# evalsoc register map
Vendor: Nuclei; Series: Nuclei Evaluation SoC
CPU: Evalsoc, little endian
Registers are 32-bit, read-write, reset 0x0 unless marked. A register's access mark holds for its fields unless they carry their own. Offsets are from the block's base; [hi:lo] are bit positions; 'fields as' and 'values as' point back to an identical list.

## IINFO — Some internal information is defined here by memory map registers. IINFO shows internal peripherals configurations or controls some micro-architecture functions.
Base 0x18000000
0x00 mpasize ro — Physical Size register. Shows the physical address size supported by the hardware.
  [31:0] PA_SIZE — Physical Size. If the PA_SIZE is 48, the number of this register is 48.
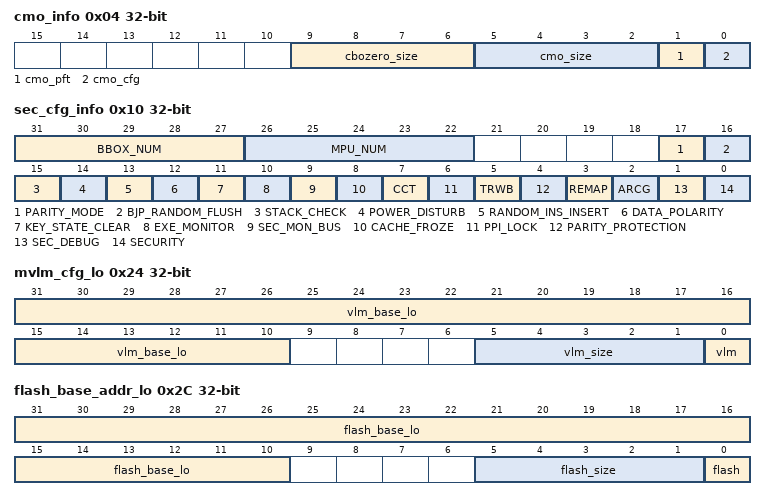
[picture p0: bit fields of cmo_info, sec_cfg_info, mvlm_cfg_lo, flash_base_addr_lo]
0x04 cmo_info ro — Shows Nuclei series RISC-V Standard CMO implementation information.
  [9:6] cbozero_size — The size of the cache block for cbo.zero instructions.<br>0: 4 bytes<br>1: 8 bytes<br>2: 16 bytes<br>3: 32 bytes<br>4: 64 bytes<br>5: 128 bytes<br>6: 256 bytes<br>7: 512 bytes
  [5:2] cmo_size — The size of the cache block for management and prefetch instructions.<br>0: 4 bytes<br>1: 8 bytes<br>2: 16 bytes<br>3: 32 bytes<br>4: 64 bytes<br>5: 128 bytes<br>6: 256 bytes<br>7: 512 bytes<br>Currently in Nuclei series core, the size is same with D-Cache cacheline.
  [1] cmo_pft — Global configuration for CMO Extension's prefetch support:<br>0: No CMO Extension's prefetch support, the prefetch.0/prefetch.r/prefetch.w are all implemented as nop.<br>1: Has CMO Extension's prefetch support.
  [0] cmo_cfg — Global configuration for CMO Extension support:<br>0: No CMO Extension support.<br>1: Has CMO Extension support.<br>Currently in Nuclei series core, if there is D-Cache or I-Cache, then it has CMO support.
0x08 sec_base_addr_lo ro — Shows the external security controller lower 32-bit base address information.
  [31:0] sec_base_addr_lo — Security controller base address low.
0x0C sec_base_addr_hi ro — Shows the external security controller higher 32-bit base address information.
  [31:0] sec_base_addr_hi — Security controller base address high.
0x10 sec_cfg_info ro — Shows the security feature supported by CPU.
  [31:27] BBOX_NUM — The value of this field represents the number of black box debugging entries:<br>* 0: indicates that the current core does not support the black box debugging feature.<br>* Non-zero: indicates that the current core supports the black box debugging feature.
  [26:22] MPU_NUM — The value of this field represents the number of mpu entries:<br>* 0: indicates that the current core does not support the mpu feature.<br>* Non-zero: indicates that the current core supports the mpu feature.
  [17] PARITY_MODE — Parity mode, only active when parity_protection enable.<br>* 0: 1-bit parity check mode<br>* 1: 4-bit parity check mode.
  [16] BJP_RANDOM_FLUSH — BJP instruction can send random flush feature support:<br>* 0: Not support<br>* 1: Support
  [15] STACK_CHECK — Stack check feature support:<br>* 0: Not support<br>* 1: Support
  [14] POWER_DISTURB — Power scrambling feature support.<br>* 0: Not support<br>* 1: Support
  [13] RANDOM_INS_INSERT — Random instruction insert feature support.<br>* 0: Not support<br>* 1: Support
  [12] DATA_POLARITY — Data polarity feature support.<br>* 0: Not support<br>* 1: Support
  [11] KEY_STATE_CLEAR — Key state clear feature support.<br>* 0: Not support<br>* 1: Support
  [10] EXE_MONITOR — Execution monitor feature support.<br>* 0: Not support<br>* 1: Support, Core will output some internal signal.
  [9] SEC_MON_BUS — Security monitor bus feature support:<br>* 0: Not support<br>* 1: Support, Core will output some error information on this bus.
  [8] CACHE_FROZE — Cache Frozen feature support:<br>* 0: Not support<br>* 1: Support, cache miss will not refill data into cache to protect the secure and critical code.
  [7] CCT — Instruction execution time consistency feature support:<br>* 0: Not support<br>* 1: Support
  [6] PPI_LOCK — PPI Lock feature support:<br>* 0: Not support<br>* 1: Support
  [5] TRWB — Garbage register write-back feature support:<br>* 0: Not support<br>* 1: Support
  [4] PARITY_PROTECTION — Register parity protection feature support:<br>* 0: Not support<br>* 1: Support
  [3] REMAP — Vector table remap feature support:<br>* 0: Not support<br>* 1: Support
  [2] ARCG — Architecture random clock gate feature support:<br>* 0: Not support<br>* 1: Support
  [1] SEC_DEBUG — Secure debug feature support:<br>* 0: Not support<br>* 1: Support
  [0] SECURITY — Security feature support:<br>* 0: Not support<br>* 1: Support
0x24 mvlm_cfg_lo ro — Shows the VLM configurations information (lower 32 bits).
  [31:10] vlm_base_lo — VLM base address [31:10]
  [5:1] vlm_size — 0: 0 bytes<br>1: 1K bytes<br>2: 2K bytes<br>3: 4K bytes<br>4: 8K bytes<br>5: 16K bytes<br>6: 32K bytes<br>7: 64K bytes<br>8: 128K bytes<br>9: 256K bytes<br>10: 512K bytes<br>11: 1M bytes<br>12: 2M bytes<br>13: 4M bytes<br>14: 8M bytes<br>15: 16M bytes<br>16: 32M bytes<br>17: 64M bytes<br>18: 128M bytes<br>19: 256M bytes<br>20: 512M bytes<br>21: 1G bytes<br>22: 2G bytes<br>23: 4G bytes<br>others: reserved
  [0] vlm — Shows the hardware has VLM configuration or not. 0 means no, 1 means yes.
0x28 mvlm_cfg_hi ro — Shows the higher 32 bit of VLM base address.
  [31:0] vlm_base_hi — VLM base address high.
0x2C flash_base_addr_lo ro — Shows the flash bus configurations information (lower 32 bits).
  [31:10] flash_base_lo — flash bus base address [31:10]
  [5:1] flash_size — 0: 0 bytes<br>1: 1K bytes<br>2: 2K bytes<br>3: 4K bytes<br>4: 8K bytes<br>5: 16K bytes<br>6: 32K bytes<br>7: 64K bytes<br>8: 128K bytes<br>9: 256K bytes<br>10: 512K bytes<br>11: 1M bytes<br>12: 2M bytes<br>13: 4M bytes<br>14: 8M bytes<br>15: 16M bytes<br>16: 32M bytes<br>17: 64M bytes<br>18: 128M bytes<br>19: 256M bytes<br>20: 512M bytes<br>21: 1G bytes<br>22: 2G bytes<br>23: 4G bytes<br>others: reserved
  [0] flash — Shows the hardware has flash bus configuration or not.<br>0: means no<br>1: means yes.
0x30 flash_base_addr_hi ro — Shows the higher 32 bit of flash bus base address.
  [31:0] flash_base_hi — Flash bus information
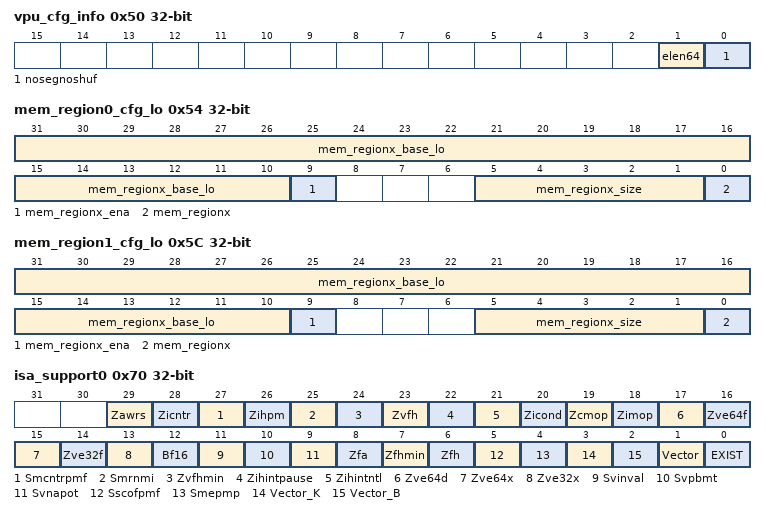
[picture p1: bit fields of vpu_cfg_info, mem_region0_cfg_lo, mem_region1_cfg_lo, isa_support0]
0x50 vpu_cfg_info ro — Shows the VPU configurations information.
  [1] elen64 — 1: Support elen=64 when configure VPU<br>0: No support elen=64 when configure VPU
  [0] nosegnoshuf — 1: No segment and no shuf feature when configure VPU<br>0: Support segment and shuf feature when configure VPU
0x54 mem_region0_cfg_lo — Hardware memory-region0 information (lower 32 bits).
  [31:10] mem_regionx_base_lo ro — mem_regionx's low 32 bits base address(aligned 1k)
  [9] mem_regionx_ena — 0: disable<br>1: enable
  [5:1] mem_regionx_size ro — 0: 0 bytes<br>1: 1K bytes<br>2: 2K bytes<br>3: 4K bytes<br>4: 8K bytes<br>5: 16K bytes<br>6: 32K bytes<br>7: 64K bytes<br>8: 128K bytes<br>9: 256K bytes<br>10: 512K bytes<br>11: 1M bytes<br>12: 2M bytes<br>13: 4M bytes<br>14: 8M bytes<br>15: 16M bytes<br>16: 32M bytes<br>17: 64M bytes<br>18: 128M bytes<br>19: 256M bytes<br>20: 512M bytes<br>21: 1G bytes<br>22: 2G bytes<br>23: 4G bytes<br>others: reserved
  [0] mem_regionx ro — 0: don't support mem_regionx<br>1: support mem_regionx
0x58 mem_region0_cfg_hi ro — Hardware memory-region0 information (higher 32 bits).
  [31:0] mem_regionx_base_hi — mem_regionx's high 32 bits base address
0x5C mem_region1_cfg_lo — Hardware memory-region1 information (lower 32 bits).
  fields as mem_region0_cfg_lo
0x60 mem_region1_cfg_hi ro — Hardware memory-region1 information (higher 32 bits).
  [31:0] mem_regionx_base_hi — mem_regionx's high 32 bits base address
0x70 isa_support0 ro — Shows the hardware support RISC-V ISA (part 0).
  [29] Zawrs — Zawrs extension support.
  [28] Zicntr — Zicntr extension support.
  [27] Smcntrpmf — Smcntrpmf extension support.
  [26] Zihpm — Zihpm extension support.
  [25] Smrnmi — Smrnmi extension support.
  [24] Zvfhmin — Zvfhmin extension support.
  [23] Zvfh — Zvfh extension support.
  [22] Zihintpause — Zihintpause extension support.
  [21] Zihintntl — Zihintntl extension support.
  [20] Zicond — Zicond extension support.
  [19] Zcmop — Zcmop extension support.
  [18] Zimop — Zimop extension support.
  [17] Zve64d — Zve64d extension support.
  [16] Zve64f — Zve64f extension support.
  [15] Zve64x — Zve64x extension support.
  [14] Zve32f — Zve32f extension support.
  [13] Zve32x — Zve32x extension support.
  [12] Bf16 — Bf16 extension support.
  [11] Svinval — Svinval extension support.
  [10] Svpbmt — Svpbmt extension support.
  [9] Svnapot — Svnapot extension support.
  [8] Zfa — Zfa extension support.
  [7] Zfhmin — Zfhmin extension support.
  [6] Zfh — Zfh extension support.
  [5] Sscofpmf — Sscofpmf extension support.
  [4] Smepmp — Smepmp extension support.
  [3] Vector_K — Vector-K extension support.
  [2] Vector_B — Vector-B extension support.
  [1] Vector — Vector extension support.
  [0] EXIST — This register exist.<br>1: This register exist<br>0: This register it not exist
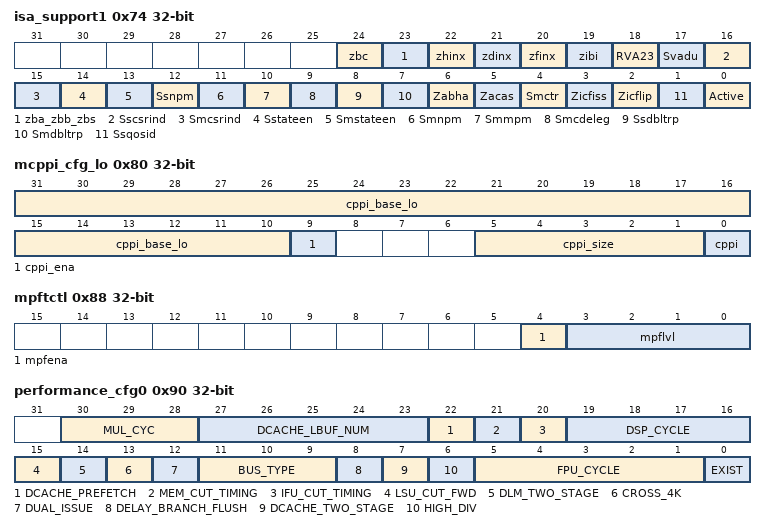
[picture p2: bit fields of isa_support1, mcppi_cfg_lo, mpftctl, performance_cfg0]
0x74 isa_support1 ro — Shows the hardware support RISC-V ISA (part 1).
  [24] zbc — zbc extension support.
  [23] zba_zbb_zbs — zba_zbb_zbs extension support.
  [22] zhinx — zhinx extension support.
  [21] zdinx — zdinx extension support.
  [20] zfinx — zfinx extension support.
  [19] zibi — extension support for branch with immediate.
  [18] RVA23 — RVA23 extension support.
  [17] Svadu — Svadu extension support.
  [16] Sscsrind — Sscsrind extension support.
  [15] Smcsrind — Smcsrind extension support.
  [14] Sstateen — Sstateen extension support.
  [13] Smstateen — Smstateen extension support.
  [12] Ssnpm — Ssnpm extension support.
  [11] Smnpm — Smnpm extension support.
  [10] Smmpm — Smmpm extension support.
  [9] Smcdeleg — Smcdeleg extension support.
  [8] Ssdbltrp — Ssdbltrp extension support.
  [7] Smdbltrp — Smdbltrp extension support.
  [6] Zabha — Zabha extension support.
  [5] Zacas — Zacas extension support.
  [4] Smctr — Smctr extension support.
  [3] Zicfiss — Zicfiss extension support.
  [2] Zicflip — Zicflip extension support.
  [1] Ssqosid — Ssqosid extension support.
  [0] Active — This register active.<br>1: This register active<br>0: This register it not active
0x80 mcppi_cfg_lo — Shows the CPPI configurations information (lower 32 bits).
  [31:10] cppi_base_lo ro — CPPI base address [31:10]
  [9] cppi_ena — Enable CPPI or not, default is 1 (enable).
  [5:1] cppi_size ro — 0: 0 bytes<br>1: 1K bytes<br>2: 2K bytes<br>3: 4K bytes<br>4: 8K bytes<br>5: 16K bytes<br>6: 32K bytes<br>7: 64K bytes<br>8: 128K bytes<br>9: 256K bytes<br>10: 512K bytes<br>11: 1M bytes<br>12: 2M bytes<br>13: 4M bytes<br>14: 8M bytes<br>15: 16M bytes<br>16: 32M bytes<br>17: 64M bytes<br>18: 128M bytes<br>19: 256M bytes<br>20: 512M bytes<br>21: 1G bytes<br>22: 2G bytes<br>23: 4G bytes<br>others: reserved
  [0] cppi ro — Shows the hardware has CPPI configuration or not. 0 means no, 1 means yes.
0x84 mcppi_cfg_hi ro — Shows the higher 32 bit of CPPI base address.
  [31:0] cppi_base_hi — Higher 32 bit of CPPI base address
0x88 mpftctl — Controls the configuration of the power brake feature (slow mode) in Low Power Mode.
  [4] mpfena — turn on the power brake when set, and off when clear.
  [3:0] mpflvl — set the duration of power brake.
0x90 performance_cfg0 ro — Shows the hardware information about performance (part 0).
  [30:28] MUL_CYC — Multiplier cycle. If 0, not support multiplier
  [27:23] DCACHE_LBUF_NUM — Dcache line buffer number. If 0, not support Dcache
  [22] DCACHE_PREFETCH — Dcache prefetch has config. 1: Has config, 0: Not has config
  [21] MEM_CUT_TIMING — MEM cut timing has config. 1: Has config, 0: Not has config
  [20] IFU_CUT_TIMING — IFU cut timing has config. 1: Has config, 0: Not has config
  [19:16] DSP_CYCLE — DSP cycle. If 0, not support DSP.
  [15] LSU_CUT_FWD — LSU cut forwarding has config. 1: Has config, 0: Not has config
  [14] DLM_TWO_STAGE — DLM two stage has config. 1: Has config, 0: Not has config
  [13] CROSS_4K — Cross 4K has config. 1: Has config, 0: Not has config
  [12] DUAL_ISSUE — Dual Issue has config. 1: Has config, 0: Not has config
  [11:9] BUS_TYPE — The memory bus protocol type. 0: ICB BUS, 1: AXI BUS, 2: AHBL BUS
  [8] DELAY_BRANCH_FLUSH — Delay branch flush has config. 1: Has config, 0: Not Has config
  [7] DCACHE_TWO_STAGE — Dcache two stage has config. 1: Has config, 0: Not Has config
  [6] HIGH_DIV — High Performance Divider Support. 1: Support, 0: Not support
  [5:1] FPU_CYCLE — FPU cycle count. If 0, not support FPU.
  [0] EXIST — This register exist. 1: This register exist, 0: This register it not exist
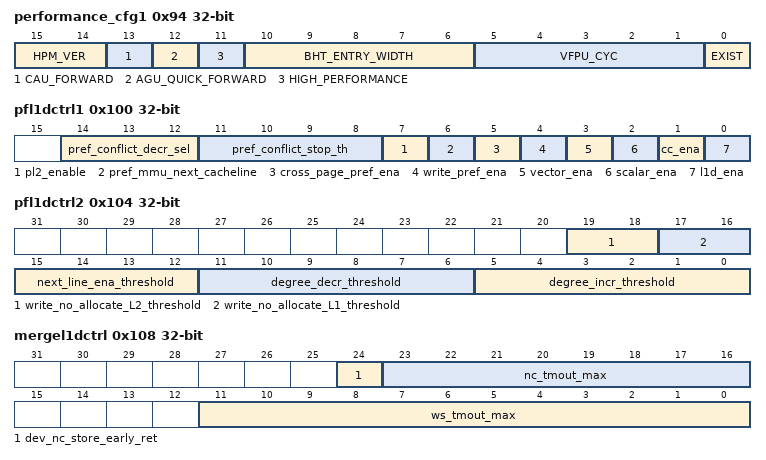
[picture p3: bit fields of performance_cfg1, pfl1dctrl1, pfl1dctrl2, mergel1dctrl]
0x94 performance_cfg1 ro — Shows the hardware information about performance (part 1).
  [15:14] HPM_VER — Hardware performance monitor version. 2: Version 2, 1: Version 1, 0: Not support
  [13] CAU_FORWARD — Crypto instruction forward has config. 1: Has config, 0: Not Has config
  [12] AGU_QUICK_FORWARD — Agu quick forward has config. 1: Has config, 0: Not Has config
  [11] HIGH_PERFORMANCE — High performance has config. 1: Has config, 0: Not Has config
  [10:6] BHT_ENTRY_WIDTH — BHT entry width config. The value is CFG_BHT_ENTRY_WIDTH-9
  [5:1] VFPU_CYC — Vector FPU cycle count. If 0, not support Vector FPU.
  [0] EXIST — This register exist. 1: This register exist, 0: This register it not exist
0x100 pfl1dctrl1 — Controls L1 D-Cache prefetch functions.
  [14:12] pref_conflict_decr_sel — decrease the conflict counter when a number of prefetch is sent. This field select how the number of prefetch:<br>0: disable<br>1: 1024 prefetches<br>2: 512 prefetches<br>3: 256<br>4: 128<br>5: 64<br>6: 32<br>7: 16
  [11:8] pref_conflict_stop_th — when prefetch has Dcache hit, a counter is increased. When the counter is greater than this threshold, the prefetch is stopped
  [7] pl2_enable — Enable PL2 prefetching. 0: Disable, 1: Enable
  [6] pref_mmu_next_cacheline — When a table walk access for a miss occurs in the MMU, prefetch the next cacheline that is incremented. 0: Disable, 1: Enable
  [5] cross_page_pref_ena — Prefetch cross page enable. 0: Disable, 1: Enable
  [4] write_pref_ena — Store prefetch enable. 0: Disable, 1: Enable
  [3] vector_ena — Vector pipeline prefetch enable. 0: Disable, 1: Enable
  [2] scalar_ena — Scalar pipeline prefetch enable. 0: Disable, 1: Enable
  [1] cc_ena — Cluster Cache prefetch enable. 0: Disable, 1: Enable
  [0] l1d_ena — L1 D-Cache prefetch enable. 0: Disable, 1: Enable
0x104 pfl1dctrl2 — Controls prefetch degree and write streaming thresholds.
  [19:18] write_no_allocate_L2_threshold — Write streaming no-L2-allocate threshold. The possible values are:<br>0b00 16th consecutive streaming cache line does not allocate in the L2 cache. This is the reset value.<br>0b01 128th consecutive streaming cache line does not allocate in the L2 cache.<br>0b10 512th consecutive streaming cache line does not allocate in the L2 cache.<br>0b11 Disables streaming. All write-allocate lines allocate in the L2 cache.
  [17:16] write_no_allocate_L1_threshold — Write streaming no-L1-allocate threshold. The possible values are:<br>0b00 4th consecutive streaming cache line does not allocate in the L1 cache. This is the reset value.<br>0b01 64th consecutive streaming cache line does not allocate in the L1 cache.<br>0b10 128th consecutive streaming cache line does not allocate in the L1 cache.<br>0b11 Disables streaming. All write-allocate lines allocate in the L1 cache.
  [15:12] next_line_ena_threshold — Threshold of enabling next-line mode prefetch. The next line prefetch mode is enabled when the proportion of Dcache miss commands to all commands is less than threshold/16.
  [11:6] degree_decr_threshold — Prefetch degree threshold of decreasing. When the accuracy of a certain prefetch is less than the threshold, the prefetch degree is decreased.
  [5:0] degree_incr_threshold — Prefetch degree threshold of increasing. When the accuracy of a certain prefetch is greater than the threshold, the prefetch degree is increased.
0x108 mergel1dctrl — Controls write streaming and non-cacheable merge related features.
  [24] dev_nc_store_early_ret — It is to control the core to treat the device and non-cacheable region store is non-blocking (earlier return) or blocking.<br>1: device and non-cacheable region store is non-blocking.<br>0: device and non-cacheable region store is blocking.
  [23:16] nc_tmout_max — Non-cacheable Merge Buffer timer out counter max value. The number indicate how many cycles core will wait to merge the Non-Cacheable Merge Buffer. If this value is non-zero, it supports the early response of non-cacheable region.
  [11:0] ws_tmout_max — Write Streaming Merge Buffer timer out counter max value. The number indicate how many cycles core will wait to merge the Write Streaming Buffer.
0x110 safety_ctrl — Controls safety features.
  [1:0] REG_PROT_CHCK_EN — Register protect check enable.<br>* 2'b01: Disable (Default)<br>* 2'b10: Enable<br>If value is 2'b00 or 2'b11, the error will on output reg_prot_err_pulse.
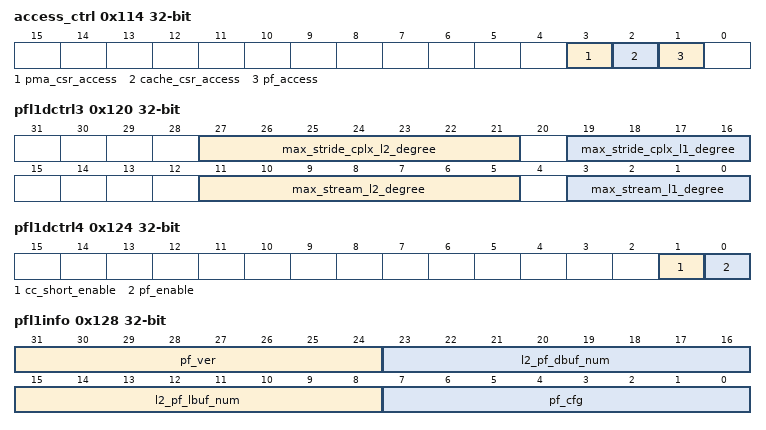
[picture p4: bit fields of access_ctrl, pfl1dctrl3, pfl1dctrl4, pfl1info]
0x114 access_ctrl — Controls IINFO registers can be accessed in S-mode.
  [3] pma_csr_access — Control access permission of mattribute CSR in S-mode. 0: Disable S-mode access, 1: Enable S-mode access
  [2] cache_csr_access — Control access permission of cache_ctrl CSR in S-mode. 0: Disable S-mode access, 1: Enable S-mode access
  [1] pf_access — S-mode can access prefetch/write streaming/merge related registers. 0: Enable(Default), 1: Disable. Currently this bit controls 5 registers: pfl1dctrl1, pfl1dctrl2, pfl1dctrl3, pfl1dctrl4, mergel1dctrl
0x120 pfl1dctrl3 — Controls Cluster Cache prefetch functions.
  [27:21] max_stride_cplx_l2_degree — The max stride/cplx prefetch L2 degree.
  [19:16] max_stride_cplx_l1_degree — The max stride/cplx prefetch L1 degree.
  [11:5] max_stream_l2_degree — The max stream prefetch l2 degree.
  [3:0] max_stream_l1_degree — The max stream prefetch L1 degree.
0x124 pfl1dctrl4 — Controls Cache prefetch overall enable.
  [1] cc_short_enable — Cc_short enable. 0: Disable cc_short, 1: Enable cc_short(Reduce the latency of L2 cache hit)
  [0] pf_enable — The prefetch overall enable. 0: Disable prefetch, 1: Enable prefetch
0x128 pfl1info ro — Shows prefetch feature information.
  [31:24] pf_ver — Prefetch Version
  [23:16] l2_pf_dbuf_num — L2 prefetch data buffer number
  [15:8] l2_pf_lbuf_num — L2 prefetch request address buffer number
  [7:0] pf_cfg — 0: No Hardware Prefetch<br>1: Normal Hardware Prefetch<br>2: High Performance Hardware Prefetch<br>Other: Reserved
0x198 crc_rf0 — Register x22 CRC value.
  [31:0] crc — The x22 register CRC value.
0x19C crc_rf1 — Register x23 CRC value.
  [31:0] crc — The x23 register CRC value.
0x1A0 crc_fp0 — Register f23 CRC value.
  [31:0] crc — The f23 register CRC value.
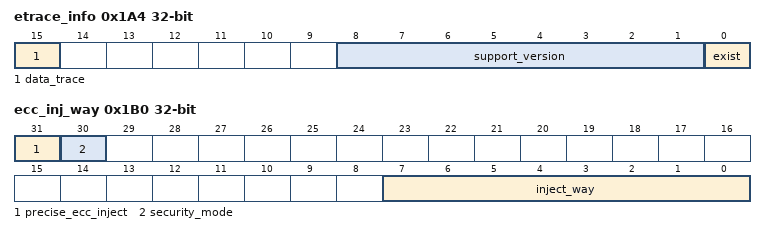
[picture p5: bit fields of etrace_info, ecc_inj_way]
0x1A4 etrace_info ro — Provides the relevant configuration information for etrace.
  [15] data_trace — rtl support the feature of data trace. 0: not support the feature of data trace, 1: support the feature of data trace
  [8:1] support_version — if the cpu supports the etrace feature, this value is 0x20, indicating support the standard of 2.0 version etrace, if the cpu don't support the etrace feature, this value is 0x0
  [0] exist — rtl support the feature of etrace. 0: not support the feature of etrace, 1: support the feature of etrace
0x1A8 ecc_inj_addr_lo — Low 32-bit address of Precise ECC inject.
  [31:0] ecc_inj_addr_lo — The low 32-bit address of Precise ECC inject
0x1AC ecc_inj_addr_hi — High 32-bit address of Precise ECC inject.
  [31:0] ecc_inj_addr_hi — The high 32-bit address of Precise ECC inject
0x1B0 ecc_inj_way — Indicates the Precise ECC inject way.
  [31] precise_ecc_inject ro — rtl support the feature of precise ecc inject. 0: not support the feature of precise ecc inject, 1: support the feature of precise ecc inject
  [30] security_mode — Indicate the current security mode. 0: sec mode, 1: non-sec mode
  [7:0] inject_way — A bit set to 1 in this field indicates the corresponding way by precise ecc inject. Note: It must be One-Hot Encoding here.
0x300 mem_crc_x22_lo — Write value to this reg lower word to calculate CRC for crc x22.
0x304 mem_crc_x22_hi — Write value to this reg higher word to calculate CRC for crc x22.
0x308 mem_crc_x23_lo — Write value to this reg lower word to calculate CRC for crc x23.
0x30C mem_crc_x23_hi — Write value to this reg higher word to calculate CRC for crc x23.
0x310 mem_crc_f23_lo — Write value to this reg lower word to calculate CRC for crc f23.
0x314 mem_crc_f23_hi — Write value to this reg higher word to calculate CRC for crc f23.
